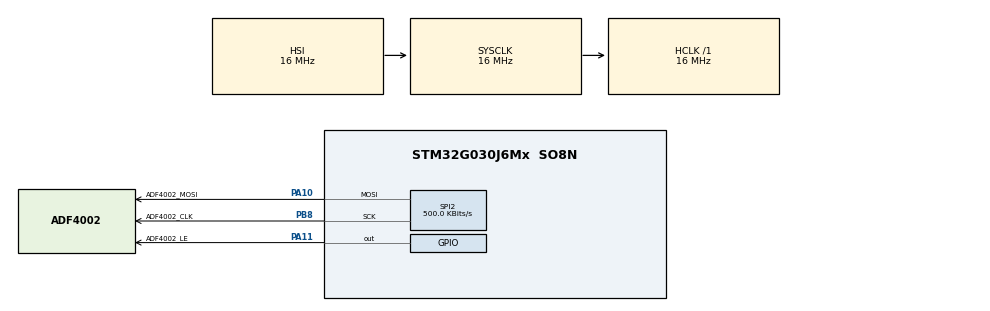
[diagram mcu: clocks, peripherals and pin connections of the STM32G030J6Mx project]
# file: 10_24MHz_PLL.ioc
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Mcu.Family=STM32G0
Mcu.Name=STM32G030J6Mx
Mcu.Package=SO8N
NRST__PA0__PA1__PA2.StandardMode=true
PA10\ [PA12].GPIO_Label=ADF4002_MOSI
PA10\ [PA12].Mode=TX_Only_Simplex_Unidirect_Master
PA10\ [PA12].Signal=SPI2_MOSI
PA11\ [PA9].GPIO_Label=ADF4002_LE
PA11\ [PA9].Signal=GPIO_Output
PA13.Mode=Serial_Wire
PA13.Signal=SYS_SWDIO
PA14-BOOT0.Mode=Serial_Wire
PA14-BOOT0.Signal=SYS_SWCLK
PA14-BOOT0__PA15__PB5__PB6.StandardMode=true
PB0__PB1__PA8__PA11\ [PA9].StandardMode=true
PB8.GPIO_Label=ADF4002_CLK
PB8.Mode=TX_Only_Simplex_Unidirect_Master
PB8.Signal=SPI2_SCK
PC14-OSC32_IN\ (PC14)__PB7__PB8__PB9.StandardMode=true
ProjectManager.HeapSize=0x200
ProjectManager.StackSize=0x400
ProjectManager.TargetToolchain=CMake
RCC.AHBFreq_Value=16000000
RCC.CortexFreq_Value=16000000
RCC.EXTERNAL_CLOCK_VALUE=12288000
RCC.HCLKFreq_Value=16000000
RCC.HSE_VALUE=8000000
RCC.HSI_VALUE=16000000
RCC.LSE_VALUE=32768
RCC.SYSCLKFreq_VALUE=16000000
RCC.VCOOutputFreq_Value=128000000
SPI2.BaudRatePrescaler=SPI_BAUDRATEPRESCALER_32
SPI2.CalculateBaudRate=500.0 KBits/s
SPI2.Direction=SPI_DIRECTION_2LINES
SPI2.Mode=SPI_MODE_MASTER
SPI2.NSSPMode=SPI_NSS_PULSE_DISABLE
SPI2.VirtualType=VM_MASTER
VP_SYS_VS_PINREMAP_10_12.Mode=PINREMAP_10_12
board=custom

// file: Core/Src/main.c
/* USER CODE BEGIN Header */
/**
  ******************************************************************************
  * @file           : main.c
  * @brief          : Main program body
  ******************************************************************************
  * @attention
  *
  * Copyright (c) 2026 STMicroelectronics.
  * All rights reserved.
  *
  * This software is licensed under terms that can be found in the LICENSE file
  * in the root directory of this software component.
  * If no LICENSE file comes with this software, it is provided AS-IS.
  *
  ******************************************************************************
  */
/* USER CODE END Header */
#include "main.h"
#include "spi.h"
#include "gpio.h"

/* USER CODE BEGIN Includes */
#include "adf4002.h"
/* USER CODE END Includes */

void SystemClock_Config(void);

int main(void)
{

  /* MCU Configuration--------------------------------------------------------*/

  /* Reset of all peripherals, Initializes the Flash interface and the Systick. */
  HAL_Init();

  /* Configure the system clock */
  SystemClock_Config();

  /* Initialize all configured peripherals */
  MX_GPIO_Init();
  MX_SPI2_Init();
  /* USER CODE BEGIN 2 */
  HAL_Delay(2000);
  if (ADF4002_Init() != HAL_OK)
  {
      Error_Handler();
  }
  /* USER CODE END 2 */

  /* Infinite loop */
  while (1)
  {

  }
}

void SystemClock_Config(void)
{
  RCC_OscInitTypeDef RCC_OscInitStruct = {0};
  RCC_ClkInitTypeDef RCC_ClkInitStruct = {0};

  /** Configure the main internal regulator output voltage
  */
  HAL_PWREx_ControlVoltageScaling(PWR_REGULATOR_VOLTAGE_SCALE1);

  /** Initializes the RCC Oscillators according to the specified parameters
  * in the RCC_OscInitTypeDef structure.
  */
  RCC_OscInitStruct.OscillatorType = RCC_OSCILLATORTYPE_HSI;
  RCC_OscInitStruct.HSIState = RCC_HSI_ON;
  RCC_OscInitStruct.HSIDiv = RCC_HSI_DIV1;
  RCC_OscInitStruct.HSICalibrationValue = RCC_HSICALIBRATION_DEFAULT;
  RCC_OscInitStruct.PLL.PLLState = RCC_PLL_NONE;
  if (HAL_RCC_OscConfig(&RCC_OscInitStruct) != HAL_OK)
  {
    Error_Handler();
  }

  /** Initializes the CPU, AHB and APB buses clocks
  */
  RCC_ClkInitStruct.ClockType = RCC_CLOCKTYPE_HCLK|RCC_CLOCKTYPE_SYSCLK
                              |RCC_CLOCKTYPE_PCLK1;
  RCC_ClkInitStruct.SYSCLKSource = RCC_SYSCLKSOURCE_HSI;
  RCC_ClkInitStruct.AHBCLKDivider = RCC_SYSCLK_DIV1;
  RCC_ClkInitStruct.APB1CLKDivider = RCC_HCLK_DIV1;

  if (HAL_RCC_ClockConfig(&RCC_ClkInitStruct, FLASH_LATENCY_0) != HAL_OK)
  {
    Error_Handler();
  }
}

void Error_Handler(void)
{
  __disable_irq();
  while (1)
  {
  }
}
